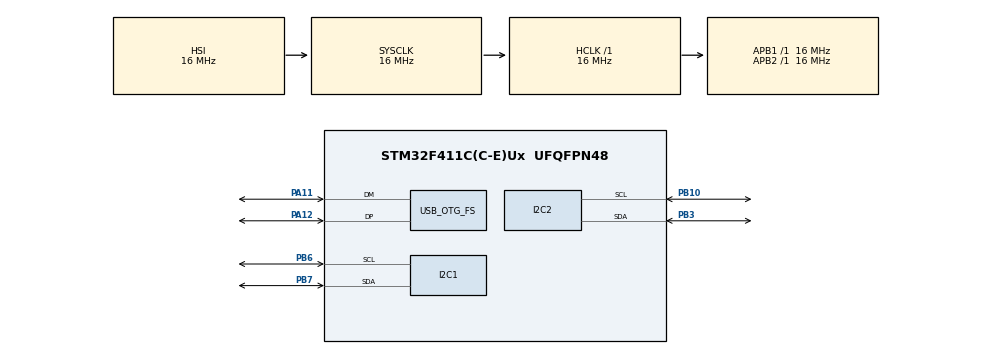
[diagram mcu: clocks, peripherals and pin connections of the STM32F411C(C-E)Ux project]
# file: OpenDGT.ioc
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I2C2.GeneralCallMode=I2C_GENERALCALL_ENABLE
I2C2.OwnAddress=16
Mcu.Family=STM32F4
Mcu.Name=STM32F411C(C-E)Ux
Mcu.Package=UFQFPN48
NVIC.I2C1_EV_IRQn=true\:0\:0\:false\:false\:true\:true\:true\:true
NVIC.I2C2_EV_IRQn=true\:0\:0\:false\:false\:true\:true\:true\:true
NVIC.OTG_FS_IRQn=true\:0\:0\:false\:false\:true\:false\:true\:true
NVIC.PriorityGroup=NVIC_PRIORITYGROUP_4
PA11.Mode=Device_Only
PA11.Signal=USB_OTG_FS_DM
PA12.Mode=Device_Only
PA12.Signal=USB_OTG_FS_DP
PB10.Mode=I2C
PB10.Signal=I2C2_SCL
PB3.Mode=I2C
PB3.Signal=I2C2_SDA
PB6.Mode=I2C
PB6.Signal=I2C1_SCL
PB7.Mode=I2C
PB7.Signal=I2C1_SDA
PH0\ -\ OSC_IN.Mode=HSE-External-Oscillator
PH0\ -\ OSC_IN.Signal=RCC_OSC_IN
PH1\ -\ OSC_OUT.Mode=HSE-External-Oscillator
PH1\ -\ OSC_OUT.Signal=RCC_OSC_OUT
ProjectManager.HeapSize=0x200
ProjectManager.StackSize=0x400
ProjectManager.TargetToolchain=Makefile
RCC.48MHZClocksFreq_Value=48000000
RCC.AHBFreq_Value=16000000
RCC.APB1Freq_Value=16000000
RCC.APB2Freq_Value=16000000
RCC.CortexFreq_Value=16000000
RCC.HSE_VALUE=25000000
RCC.HSI_VALUE=16000000
RCC.LSE_VALUE=32768
RCC.PLLM=15
RCC.PLLN=144
RCC.PLLQ=5
RCC.SYSCLKFreq_VALUE=16000000
RCC.VCOOutputFreq_Value=240000000
USB_DEVICE.CLASS_NAME_FS=CDC
USB_DEVICE.VirtualMode=Cdc
USB_DEVICE.VirtualModeFS=Cdc_FS
USB_OTG_FS.VirtualMode=Device_Only
VP_USB_DEVICE_VS_USB_DEVICE_CDC_FS.Mode=CDC_FS
board=custom

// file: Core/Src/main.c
/* USER CODE BEGIN Header */
/**
  ******************************************************************************
  * @file           : main.c
  * @brief          : Main program body
  ******************************************************************************
  * @attention
  *
  * Copyright (c) 2026 STMicroelectronics.
  * All rights reserved.
  *
  * This software is licensed under terms that can be found in the LICENSE file
  * in the root directory of this software component.
  * If no LICENSE file comes with this software, it is provided AS-IS.
  *
  ******************************************************************************
  */
/* USER CODE END Header */
#include "main.h"
#include "usb_device.h"

/* USER CODE BEGIN Includes */
#include "opendgtlib.h"
#include "dgt_port.h"

/* USER CODE END Includes */

I2C_HandleTypeDef hi2c1;
I2C_HandleTypeDef hi2c2;

/* USER CODE BEGIN PV */
char usb_buffer[12];
/* USER CODE END PV */

void SystemClock_Config(void);
static void MX_GPIO_Init(void);
static void MX_I2C1_Init(void);
static void MX_I2C2_Init(void);

int main(void)
{

  /* MCU Configuration--------------------------------------------------------*/

  /* Reset of all peripherals, Initializes the Flash interface and the Systick. */
  HAL_Init();

  /* Configure the system clock */
  SystemClock_Config();

  /* Initialize all configured peripherals */
  MX_GPIO_Init();
  MX_I2C1_Init();
  MX_I2C2_Init();
  MX_USB_DEVICE_Init();
  /* USER CODE BEGIN 2 */
  DGT_Port_Init();
  DGT3000_WakeClock();
  /* Like dgtpi, try the display even if configuring reported a failure */
  volatile int configure_status = DGT3000_Configure();
  volatile int display_status = DGT3000_Display("1999", 0, 0, 0);
  (void)configure_status;
  (void)display_status;
  /* USER CODE END 2 */

  /* Infinite loop */
  while (1)
  {
    HAL_Delay(1000);
    DGT3000_Display(usb_buffer,0,0,0);
  }
}

void SystemClock_Config(void)
{
  RCC_OscInitTypeDef RCC_OscInitStruct = {0};
  RCC_ClkInitTypeDef RCC_ClkInitStruct = {0};

  /** Configure the main internal regulator output voltage
  */
  __HAL_RCC_PWR_CLK_ENABLE();
  __HAL_PWR_VOLTAGESCALING_CONFIG(PWR_REGULATOR_VOLTAGE_SCALE1);

  /** Initializes the RCC Oscillators according to the specified parameters
  * in the RCC_OscInitTypeDef structure.
  */
  RCC_OscInitStruct.OscillatorType = RCC_OSCILLATORTYPE_HSI|RCC_OSCILLATORTYPE_HSE;
  RCC_OscInitStruct.HSEState = RCC_HSE_ON;
  RCC_OscInitStruct.HSIState = RCC_HSI_ON;
  RCC_OscInitStruct.HSICalibrationValue = RCC_HSICALIBRATION_DEFAULT;
  RCC_OscInitStruct.PLL.PLLState = RCC_PLL_ON;
  RCC_OscInitStruct.PLL.PLLSource = RCC_PLLSOURCE_HSE;
  RCC_OscInitStruct.PLL.PLLM = 15;
  RCC_OscInitStruct.PLL.PLLN = 144;
  RCC_OscInitStruct.PLL.PLLP = RCC_PLLP_DIV2;
  RCC_OscInitStruct.PLL.PLLQ = 5;
  if (HAL_RCC_OscConfig(&RCC_OscInitStruct) != HAL_OK)
  {
    Error_Handler();
  }

  /** Initializes the CPU, AHB and APB buses clocks
  */
  RCC_ClkInitStruct.ClockType = RCC_CLOCKTYPE_HCLK|RCC_CLOCKTYPE_SYSCLK
                              |RCC_CLOCKTYPE_PCLK1|RCC_CLOCKTYPE_PCLK2;
  RCC_ClkInitStruct.SYSCLKSource = RCC_SYSCLKSOURCE_HSI;
  RCC_ClkInitStruct.AHBCLKDivider = RCC_SYSCLK_DIV1;
  RCC_ClkInitStruct.APB1CLKDivider = RCC_HCLK_DIV1;
  RCC_ClkInitStruct.APB2CLKDivider = RCC_HCLK_DIV1;

  if (HAL_RCC_ClockConfig(&RCC_ClkInitStruct, FLASH_LATENCY_0) != HAL_OK)
  {
    Error_Handler();
  }
}

static void MX_I2C1_Init(void)
{

  hi2c1.Instance = I2C1;
  hi2c1.Init.ClockSpeed = 100000;
  hi2c1.Init.DutyCycle = I2C_DUTYCYCLE_2;
  hi2c1.Init.OwnAddress1 = 0;
  hi2c1.Init.AddressingMode = I2C_ADDRESSINGMODE_7BIT;
  hi2c1.Init.DualAddressMode = I2C_DUALADDRESS_DISABLE;
  hi2c1.Init.OwnAddress2 = 0;
  hi2c1.Init.GeneralCallMode = I2C_GENERALCALL_DISABLE;
  hi2c1.Init.NoStretchMode = I2C_NOSTRETCH_DISABLE;
  if (HAL_I2C_Init(&hi2c1) != HAL_OK)
  {
    Error_Handler();
  }

}

static void MX_I2C2_Init(void)
{

  hi2c2.Instance = I2C2;
  hi2c2.Init.ClockSpeed = 100000;
  hi2c2.Init.DutyCycle = I2C_DUTYCYCLE_2;
  hi2c2.Init.OwnAddress1 = 32;
  hi2c2.Init.AddressingMode = I2C_ADDRESSINGMODE_7BIT;
  hi2c2.Init.DualAddressMode = I2C_DUALADDRESS_DISABLE;
  hi2c2.Init.OwnAddress2 = 0;
  hi2c2.Init.GeneralCallMode = I2C_GENERALCALL_ENABLE;
  hi2c2.Init.NoStretchMode = I2C_NOSTRETCH_DISABLE;
  if (HAL_I2C_Init(&hi2c2) != HAL_OK)
  {
    Error_Handler();
  }

}

static void MX_GPIO_Init(void)
{

  /* GPIO Ports Clock Enable */
  __HAL_RCC_GPIOH_CLK_ENABLE();
  __HAL_RCC_GPIOB_CLK_ENABLE();
  __HAL_RCC_GPIOA_CLK_ENABLE();

}

void Error_Handler(void)
{
  __disable_irq();
  while (1)
  {
  }
}
